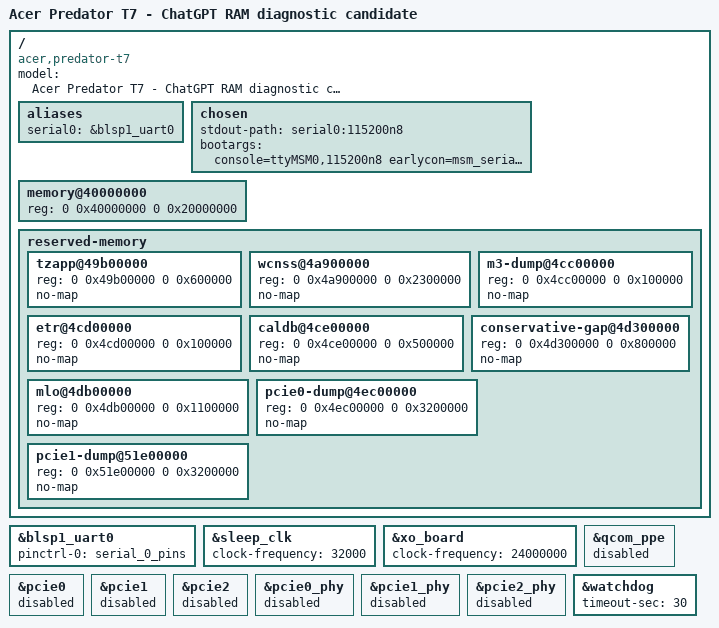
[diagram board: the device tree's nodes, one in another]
// Diagnostico candidato; NAO aprovado para upload.
/dts-v1/;
#include "qcom/ipq5332.dtsi"
/ {
    model = "Acer Predator T7 - ChatGPT RAM diagnostic candidate";
    compatible = "acer,predator-t7", "qcom,ipq5332-ap-mi01.6", "qcom,ipq5332";
    aliases { serial0 = &blsp1_uart0; };
    chosen {
        stdout-path = "serial0:115200n8";
        bootargs = "console=ttyMSM0,115200n8 earlycon=msm_serial_dm,0x78af000 loglevel=8 ignore_loglevel panic=0 maxcpus=1 rdinit=/init";
    };
    /* Conservative 512 MiB template; actual banks/fixups must be confirmed. */
    memory@40000000 { reg = <0 0x40000000 0 0x20000000>; };
    reserved-memory {
        tzapp@49b00000 { reg = <0 0x49b00000 0 0x600000>; no-map; };
        wcnss@4a900000 { reg = <0 0x4a900000 0 0x2300000>; no-map; };
        m3-dump@4cc00000 { reg = <0 0x4cc00000 0 0x100000>; no-map; };
        etr@4cd00000 { reg = <0 0x4cd00000 0 0x100000>; no-map; };
        caldb@4ce00000 { reg = <0 0x4ce00000 0 0x500000>; no-map; };
        conservative-gap@4d300000 { reg = <0 0x4d300000 0 0x800000>; no-map; };
        mlo@4db00000 { reg = <0 0x4db00000 0 0x1100000>; no-map; };
        pcie0-dump@4ec00000 { reg = <0 0x4ec00000 0 0x3200000>; no-map; };
        pcie1-dump@51e00000 { reg = <0 0x51e00000 0 0x3200000>; no-map; };
        /* No ramoops reg: exclusive location and reset retention unverified. */
    };
};
&blsp1_uart0 {
    pinctrl-0 = <&serial_0_pins>;
    pinctrl-names = "default";
    status = "okay";
};
&sleep_clk { clock-frequency = <32000>; };
&xo_board { clock-frequency = <24000000>; };
&qcom_ppe { status = "disabled"; };
&pcie0 { status = "disabled"; };
&pcie1 { status = "disabled"; };
&pcie2 { status = "disabled"; };
&pcie0_phy { status = "disabled"; };
&pcie1_phy { status = "disabled"; };
&pcie2_phy { status = "disabled"; };
&watchdog { status = "okay"; timeout-sec = <30>; };
